VERSION ""

NS_ :

BS_:

BU_: ECU TCU

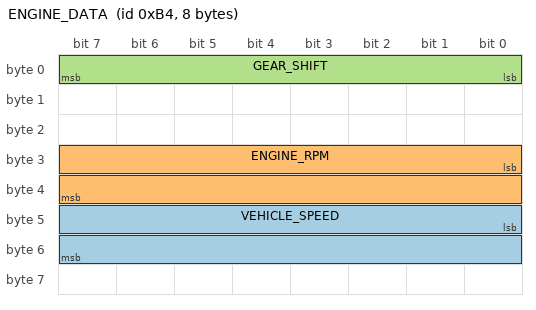
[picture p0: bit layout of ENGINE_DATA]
BO_ 180 ENGINE_DATA: 8 ECU
 SG_ VEHICLE_SPEED : 40|16@1+ (0.01,0) [0|250] "km/h" TCU
 SG_ ENGINE_RPM : 24|16@1+ (0.25,0) [0|8000] "rpm" TCU
 SG_ GEAR_SHIFT : 0|8@1+ (1,0) [0|4] "" TCU

BO_ 452 ENGINE_TEMP: 8 ECU
 SG_ ENGINE_COOLANT_TEMP : 0|8@1+ (1,-40) [-40|215] "degC" TCU

BO_ 947 BATTERY_DATA: 8 ECU
 SG_ BATTERY_VOLTAGE : 0|8@1+ (0.1,0) [0|25.5] "V" TCU
